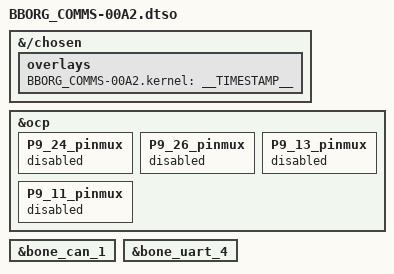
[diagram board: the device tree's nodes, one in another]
// SPDX-License-Identifier: GPL-2.0-only
/*
 * Copyright (C) 2012,2019 Texas Instruments Incorporated - https://www.ti.com/
 * Copyright (C) 2015 Robert Nelson <robertcnelson@gmail.com>
 * Copyright (C) 2015 Sebastian Jegerås
 */

/dts-v1/;
/plugin/;

#include <dt-bindings/pinctrl/am33xx.h>
#include <dt-bindings/gpio/gpio.h>

/*
 * Helper to show loaded overlays under: /proc/device-tree/chosen/overlays/
 */
&{/chosen} {
	overlays {
		BBORG_COMMS-00A2.kernel = __TIMESTAMP__;
	};
};

/*
 * Free up the pins used by the cape from the pinmux helpers.
 */
&ocp {
	P9_24_pinmux { status = "disabled"; };	/* P9_24: uart1_txd.d_can1_rx */
	P9_26_pinmux { status = "disabled"; };	/* P9_26: uart1_rxd.d_can1_tx */
	P9_13_pinmux { status = "disabled"; };	/* P9_13: gpmc_wpn.uart4_txd_mux2 */
	P9_11_pinmux { status = "disabled"; };	/* P9_11: gpmc_wait0.uart4_rxd_mux2 */
};

&bone_can_1 {
	status = "okay";
};

&bone_uart_4 {
	status = "okay";
};
